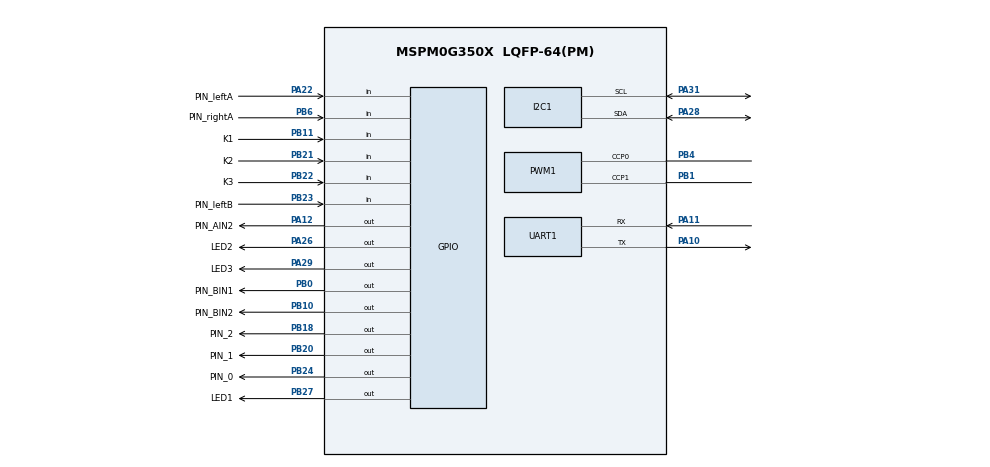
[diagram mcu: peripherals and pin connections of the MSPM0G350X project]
/**
 * @cliArgs --device "MSPM0G350X" --part "Default" --package "LQFP-64(PM)" --product "mspm0_sdk@2.10.00.04"
 * @versions {"tool":"1.28.0"}
 */

/**
 * Import the modules used in this configuration.
 */
const ADC12   = scripting.addModule("/ti/driverlib/ADC12", {}, false);
const ADC121  = ADC12.addInstance();
const GPIO    = scripting.addModule("/ti/driverlib/GPIO", {}, false);
const GPIO1   = GPIO.addInstance();
const GPIO2   = GPIO.addInstance();
const GPIO3   = GPIO.addInstance();
const GPIO4   = GPIO.addInstance();
const GPIO5   = GPIO.addInstance();
const GPIO6   = GPIO.addInstance();
const I2C     = scripting.addModule("/ti/driverlib/I2C", {}, false);
const I2C1    = I2C.addInstance();
const PWM     = scripting.addModule("/ti/driverlib/PWM", {}, false);
const PWM1    = PWM.addInstance();
const SYSCTL  = scripting.addModule("/ti/driverlib/SYSCTL");
const TIMER   = scripting.addModule("/ti/driverlib/TIMER", {}, false);
const TIMER1  = TIMER.addInstance();
const UART    = scripting.addModule("/ti/driverlib/UART", {}, false);
const UART1   = UART.addInstance();

/**
 * Write custom configuration values to the imported modules.
 */
const divider7       = system.clockTree["PLL_PDIV"];
divider7.divideValue = 2;

const divider9       = system.clockTree["UDIV"];
divider9.divideValue = 2;

const multiplier2         = system.clockTree["PLL_QDIV"];
multiplier2.multiplyValue = 5;

const mux8       = system.clockTree["HSCLKMUX"];
mux8.inputSelect = "HSCLKMUX_SYSPLL2X";

ADC121.$name                      = "ADC12_0";
ADC121.sampClkDiv                 = "DL_ADC12_CLOCK_DIVIDE_8";
ADC121.powerDownMode              = "DL_ADC12_POWER_DOWN_MODE_MANUAL";
ADC121.enabledInterrupts          = [];
ADC121.interruptPriority          = "2";
ADC121.sampleTime0                = "0ms";
ADC121.peripheral.$assign         = "ADC0";
ADC121.peripheral.adcPin0.$assign = "PA27";
ADC121.adcPin0Config.$name        = "ti_driverlib_gpio_GPIOPinGeneric2";

const Board = scripting.addModule("/ti/driverlib/Board", {}, false);

GPIO1.$name                          = "GPIO_motor";
GPIO1.associatedPins.create(4);
GPIO1.associatedPins[0].$name        = "PIN_AIN1";
GPIO1.associatedPins[0].assignedPort = "PORTA";
GPIO1.associatedPins[0].assignedPin  = "13";
GPIO1.associatedPins[1].$name        = "PIN_AIN2";
GPIO1.associatedPins[1].assignedPort = "PORTA";
GPIO1.associatedPins[1].assignedPin  = "12";
GPIO1.associatedPins[1].pin.$assign  = "PA12";
GPIO1.associatedPins[2].$name        = "PIN_BIN1";
GPIO1.associatedPins[2].assignedPort = "PORTB";
GPIO1.associatedPins[2].assignedPin  = "0";
GPIO1.associatedPins[2].pin.$assign  = "PB0";
GPIO1.associatedPins[3].$name        = "PIN_BIN2";
GPIO1.associatedPins[3].assignedPort = "PORTB";
GPIO1.associatedPins[3].assignedPin  = "10";
GPIO1.associatedPins[3].pin.$assign  = "PB10";

GPIO2.$name                          = "Gray_Address";
GPIO2.associatedPins.create(3);
GPIO2.associatedPins[0].$name        = "PIN_0";
GPIO2.associatedPins[0].assignedPort = "PORTB";
GPIO2.associatedPins[0].assignedPin  = "24";
GPIO2.associatedPins[0].pin.$assign  = "PB24";
GPIO2.associatedPins[1].$name        = "PIN_1";
GPIO2.associatedPins[1].assignedPort = "PORTB";
GPIO2.associatedPins[1].assignedPin  = "20";
GPIO2.associatedPins[1].pin.$assign  = "PB20";
GPIO2.associatedPins[2].$name        = "PIN_2";
GPIO2.associatedPins[2].assignedPort = "PORTB";
GPIO2.associatedPins[2].assignedPin  = "18";
GPIO2.associatedPins[2].pin.$assign  = "PB18";

GPIO3.$name                               = "GPIO_encoder_left";
GPIO3.associatedPins.create(2);
GPIO3.associatedPins[0].$name             = "PIN_leftA";
GPIO3.associatedPins[0].assignedPort      = "PORTA";
GPIO3.associatedPins[0].assignedPin       = "22";
GPIO3.associatedPins[0].direction         = "INPUT";
GPIO3.associatedPins[0].interruptEn       = true;
GPIO3.associatedPins[0].polarity          = "RISE";
GPIO3.associatedPins[0].interruptPriority = "1";
GPIO3.associatedPins[0].pin.$assign       = "PA22";
GPIO3.associatedPins[1].$name             = "PIN_leftB";
GPIO3.associatedPins[1].direction         = "INPUT";
GPIO3.associatedPins[1].assignedPort      = "PORTB";
GPIO3.associatedPins[1].assignedPin       = "23";
GPIO3.associatedPins[1].pin.$assign       = "PB23";

GPIO4.$name                               = "GPIO_encoder_right";
GPIO4.associatedPins.create(2);
GPIO4.associatedPins[0].$name             = "PIN_rightA";
GPIO4.associatedPins[0].direction         = "INPUT";
GPIO4.associatedPins[0].assignedPort      = "PORTB";
GPIO4.associatedPins[0].assignedPin       = "6";
GPIO4.associatedPins[0].polarity          = "RISE";
GPIO4.associatedPins[0].interruptEn       = true;
GPIO4.associatedPins[0].interruptPriority = "1";
GPIO4.associatedPins[0].pin.$assign       = "PB6";
GPIO4.associatedPins[1].$name             = "PIN_rightB";
GPIO4.associatedPins[1].direction         = "INPUT";
GPIO4.associatedPins[1].assignedPort      = "PORTA";
GPIO4.associatedPins[1].assignedPin       = "15";

GPIO5.$name                          = "KEY";
GPIO5.associatedPins.create(3);
GPIO5.associatedPins[0].$name        = "K1";
GPIO5.associatedPins[0].direction    = "INPUT";
GPIO5.associatedPins[0].assignedPort = "PORTB";
GPIO5.associatedPins[0].assignedPin  = "11";
GPIO5.associatedPins[0].pin.$assign  = "PB11";
GPIO5.associatedPins[1].$name        = "K2";
GPIO5.associatedPins[1].direction    = "INPUT";
GPIO5.associatedPins[1].assignedPort = "PORTB";
GPIO5.associatedPins[1].assignedPin  = "21";
GPIO5.associatedPins[1].pin.$assign  = "PB21";
GPIO5.associatedPins[2].$name        = "K3";
GPIO5.associatedPins[2].direction    = "INPUT";
GPIO5.associatedPins[2].assignedPort = "PORTB";
GPIO5.associatedPins[2].assignedPin  = "22";
GPIO5.associatedPins[2].pin.$assign  = "PB22";

GPIO6.$name                          = "LED";
GPIO6.associatedPins.create(3);
GPIO6.associatedPins[0].$name        = "LED1";
GPIO6.associatedPins[0].assignedPort = "PORTB";
GPIO6.associatedPins[0].assignedPin  = "27";
GPIO6.associatedPins[0].initialValue = "SET";
GPIO6.associatedPins[0].pin.$assign  = "PB27";
GPIO6.associatedPins[1].$name        = "LED2";
GPIO6.associatedPins[1].assignedPort = "PORTA";
GPIO6.associatedPins[1].assignedPin  = "26";
GPIO6.associatedPins[1].initialValue = "SET";
GPIO6.associatedPins[1].pin.$assign  = "PA26";
GPIO6.associatedPins[2].$name        = "LED3";
GPIO6.associatedPins[2].assignedPort = "PORTA";
GPIO6.associatedPins[2].assignedPin  = "29";
GPIO6.associatedPins[2].initialValue = "SET";
GPIO6.associatedPins[2].pin.$assign  = "PA29";

I2C1.$name                             = "I2C_OLED";
I2C1.basicEnableController             = true;
I2C1.basicControllerStandardBusSpeed   = "Fast";
I2C1.peripheral.sdaPin.$assign         = "PA28";
I2C1.peripheral.sclPin.$assign         = "PA31";
I2C1.sdaPinConfig.hideOutputInversion  = scripting.forceWrite(false);
I2C1.sdaPinConfig.onlyInternalResistor = scripting.forceWrite(false);
I2C1.sdaPinConfig.passedPeripheralType = scripting.forceWrite("Digital");
I2C1.sdaPinConfig.$name                = "ti_driverlib_gpio_GPIOPinGeneric5";
I2C1.sclPinConfig.hideOutputInversion  = scripting.forceWrite(false);
I2C1.sclPinConfig.onlyInternalResistor = scripting.forceWrite(false);
I2C1.sclPinConfig.passedPeripheralType = scripting.forceWrite("Digital");
I2C1.sclPinConfig.$name                = "ti_driverlib_gpio_GPIOPinGeneric6";

PWM1.$name                              = "PWM_motor";
PWM1.clockDivider                       = 2;
PWM1.clockPrescale                      = 2;
PWM1.timerStartTimer                    = true;
PWM1.pwmMode                            = "EDGE_ALIGN_UP";
PWM1.peripheral.$assign                 = "TIMA1";
PWM1.peripheral.ccp0Pin.$assign         = "PB4";
PWM1.peripheral.ccp1Pin.$assign         = "PB1";
PWM1.PWM_CHANNEL_0.$name                = "ti_driverlib_pwm_PWMTimerCC0";
PWM1.PWM_CHANNEL_1.$name                = "ti_driverlib_pwm_PWMTimerCC1";
PWM1.ccp0PinConfig.direction            = scripting.forceWrite("OUTPUT");
PWM1.ccp0PinConfig.hideOutputInversion  = scripting.forceWrite(false);
PWM1.ccp0PinConfig.onlyInternalResistor = scripting.forceWrite(false);
PWM1.ccp0PinConfig.passedPeripheralType = scripting.forceWrite("Digital");
PWM1.ccp0PinConfig.$name                = "ti_driverlib_gpio_GPIOPinGeneric0";
PWM1.ccp1PinConfig.direction            = scripting.forceWrite("OUTPUT");
PWM1.ccp1PinConfig.hideOutputInversion  = scripting.forceWrite(false);
PWM1.ccp1PinConfig.onlyInternalResistor = scripting.forceWrite(false);
PWM1.ccp1PinConfig.passedPeripheralType = scripting.forceWrite("Digital");
PWM1.ccp1PinConfig.$name                = "ti_driverlib_gpio_GPIOPinGeneric1";

SYSCTL.forceDefaultClkConfig = true;
SYSCTL.clockTreeEn           = true;
scripting.suppress("For best practices when the CPUCLK is running at 32MHz and above, clear the flash status bit using DL_FlashCTL_executeClearStatus\\(\\) before executing any flash operation\\. Otherwise there may be false positives\\.", SYSCTL);

TIMER1.$name              = "TIMER_0";
TIMER1.timerClkDiv        = 2;
TIMER1.timerClkPrescale   = 10;
TIMER1.timerPeriod        = "10ms";
TIMER1.timerStartTimer    = false;
TIMER1.interrupts         = [];
TIMER1.timerMode          = "PERIODIC";
TIMER1.interruptPriority  = "3";
TIMER1.peripheral.$assign = "TIMA0";

UART1.$name                    = "UART_0";
UART1.uartClkDiv               = "5";
UART1.peripheral.$assign       = "UART0";
UART1.peripheral.rxPin.$assign = "PA11";
UART1.peripheral.txPin.$assign = "PA10";
UART1.txPinConfig.$name        = "ti_driverlib_gpio_GPIOPinGeneric3";
UART1.rxPinConfig.$name        = "ti_driverlib_gpio_GPIOPinGeneric4";

/**
 * Pinmux solution for unlocked pins/peripherals. This ensures that minor changes to the automatic solver in a future
 * version of the tool will not impact the pinmux you originally saw.  These lines can be completely deleted in order to
 * re-solve from scratch.
 */
Board.peripheral.$suggestSolution            = "DEBUGSS";
Board.peripheral.swclkPin.$suggestSolution   = "PA20";
Board.peripheral.swdioPin.$suggestSolution   = "PA19";
GPIO1.associatedPins[0].pin.$suggestSolution = "PA13";
GPIO4.associatedPins[1].pin.$suggestSolution = "PA15";
I2C1.peripheral.$suggestSolution             = "I2C0";
